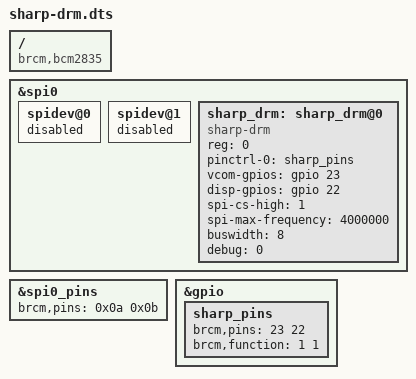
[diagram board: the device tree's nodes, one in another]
/dts-v1/;
/plugin/;

/ {
	compatible = "brcm,bcm2835", "brcm,bcm2708", "brcm,bcm2709";

	fragment@0 {
		target = <&spi0>;
		__overlay__ {
			status = "okay";

			spidev@0{
				status = "disabled";
			};

			spidev@1{
				status = "disabled";
			};
		};
	};

	fragment@1 {
		target = <&spi0_pins>;
		__overlay__ {
			brcm,pins = <0x0a 0x0b>; /* skipping bcm9 MISO */
		};
	};

	fragment@2 {
		target = <&gpio>;
		__overlay__ {
			sharp_pins: sharp_pins {
				brcm,pins = <23 22>;
				brcm,function = <1 1>; /* out */
			};
		};
	};

	fragment@3 {
		target = <&spi0>;
		__overlay__ {
			/* needed to avoid dtc warning */
			#address-cells = <1>;
			#size-cells = <0>;

#ifndef BLEPIS_V2
			sharp_drm: sharp_drm@0{
#else
			sharp_drm: sharp_drm@1{
#endif
				compatible = "sharp-drm";
#ifndef BLEPIS_V2
				reg = <0>;
#else
				// Use CE1 on GPIO7 as CS
				reg = <1>;
#endif
				pinctrl-names = "default";
				pinctrl-0 = <&sharp_pins>;

				vcom-gpios = <&gpio 23 0>;
#ifndef BLEPIS_V2
				disp-gpios = <&gpio 22 0>;
#else
				// Use GPIO6 for DISP_CE
				// not used on the Sharp LCD anyways, but GPIO22 is
				// certainly not correct anymore
				disp-gpios = <&gpio 6 0>;
#endif

				spi-cs-high = <1>;
				spi-max-frequency = <4000000>;
				buswidth = <8>;
				debug = <0>;
			};
		};
	};
};
